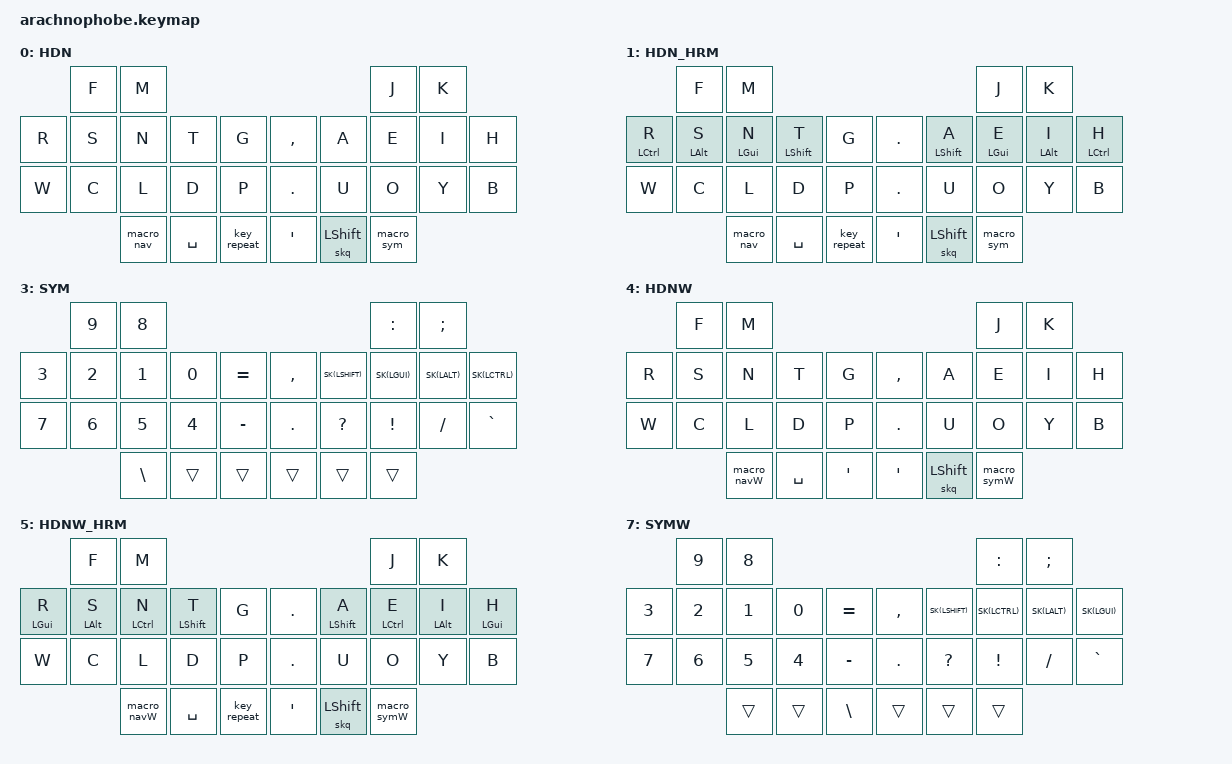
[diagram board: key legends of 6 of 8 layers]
/*
 * Copyright (c) 2020 The ZMK Contributors
 *
 * SPDX-License-Identifier: MIT
 */

#include <behaviors.dtsi>
#include <dt-bindings/zmk/keys.h>
#include <dt-bindings/zmk/rgb.h>
#include <dt-bindings/zmk/bt.h>
#include <dt-bindings/zmk/ext_power.h>
#include <dt-bindings/zmk/outputs.h>

#define HDN      0
#define HDN_HRM  1
#define NAV      2
#define SYM      3
#define HDNW     4
#define HDNW_HRM 5
#define NAVW     6
#define SYMW     7

#define SK(KEY) &nk KEY KEY

#define KEYS_L 0 1 4 5 6 7 8 14 14 15 16 17 18   // left-hand keys
#define KEYS_R 2 3 9 10 11 12 13 19 20 21 22 23  // right-hand keys
#define THUMBS 24 25 26 27 28 29                 // thumb keys

&sk {
  release-after-ms = <60000>;
  quick-release;
};

&caps_word {
  continue-list = <UNDERSCORE MINUS BACKSPACE K_CANCEL>;
};

&leader {
  timeout-ms = <500>;
};
/*                KEY POSITIONS

  ╭────────────────────────╮ ╭─────────────────────────╮
  │     0   1              │ │              2   3      │
  │ 4   5   6   7   8      │ │      9   10  11  12  13 │
  │ 14  15  16  17  18     │ │     19  20  21  22  23  │
  ╰───────╮     24  25  26 │ │ 27  28  29     ╭────────╯
          ╰────────────────╯ ╰────────────────╯            */


/ {
    behaviors {
    
        combos {
            #include "combos.dtsi"
        };

        macros {
          #include "macros.dtsi"
        };

        nk: not_so_sticky_key {
            compatible = "zmk,behavior-hold-tap";
            label = "NOT_SO_STICKY_KEY";
            #binding-cells = <2>;
            tapping_term_ms = <250>;
            flavor = "tap-preferred";
            bindings = <&kp>, <&sk>;
        };

        skq: sticky_key_quick_release {
            compatible = "zmk,behavior-sticky-key";
            label = "STICKY_KEY_QUICK_RELEASE";
            #binding-cells = <1>;
            bindings = <&kp>;
            quick-release;
            release-after-ms = <750>;
        };

    lal: layer-alpha {
        compatible = "zmk,behavior-hold-tap";
        label = "LAYER_ALPHA";
        #binding-cells = <2>;
        flavor = "balanced";
        tapping-term-ms = <170>;
        quick-tap-ms = <100>;
        global-quick-tap;
        bindings = <&mo>, <&kp>;
    };

        // Swapper for smart alt+tab depends on experimental branch: check west.yml
        swapper: swapper {
            compatible = "zmk,behavior-smart-interrupt";
            label = "SWAPPER";
            #binding-cells = <0>;
            bindings = <&kt LGUI>, <&kp TAB>, <&kt LGUI>;
            shared-key-positions = <16 18 28>;
            timeout-ms = <1000>;
        };

        // Swapper for smart alt+tab depends on experimental branch: check west.yml
        swapperw: swapperw {
            compatible = "zmk,behavior-smart-interrupt";
            label = "SWAPPERW";
            #binding-cells = <0>;
            bindings = <&kt LALT>, <&kp TAB>, <&kt LALT>;
            shared-key-positions = <16 18 28>;
            timeout-ms = <1000>;
        };

        gresc: grave_escape {
            compatible = "zmk,behavior-mod-morph";
            label = "GRAVE_ESCAPE";
            #binding-cells = <0>;
            bindings = <&kp N0>, <&kp DOT>;
            mods = <(MOD_LSFT|MOD_RSFT)>;
            masked_mods = <(MOD_LSFT|MOD_RSFT)>;
        };

        /* left-hand HRMs */
        hrml: hrml {
            compatible = "zmk,behavior-hold-tap";
            label = "hrml";
            #binding-cells = <2>;
            flavor = "balanced";
            tapping-term-ms = <280>;
            quick-tap-ms = <175>;                // double tapping same key allows for repeating
            global-quick-tap-ms = <150>;         // without PR #1387 use global-quick-tap instead
            bindings = <&kp>, <&kp>;
            hold-trigger-key-positions = <KEYS_R THUMBS>;
            hold-trigger-on-release;             // requires PR #1423
        };

        /* right-hand HRMs */
        hrmr: hrmr {
            compatible = "zmk,behavior-hold-tap";
            label = "hrmr";
            #binding-cells = <2>;
            flavor = "balanced";
            tapping-term-ms = <280>;
            quick-tap-ms = <175>;                // double tapping same key allows for repeating
            global-quick-tap-ms = <150>;         // without PR #1387 use global-quick-tap instead
            bindings = <&kp>, <&kp>;
            hold-trigger-key-positions = <KEYS_L THUMBS>;
            hold-trigger-on-release;             // requires PR #1423
        };

    };

    keymap {
        compatible = "zmk,keymap";

        hdn {
            label = "HDN";
            bindings = <
                   &kp F         &kp M                                                                     &kp J         &kp K         
     &kp R         &kp S         &kp N          &kp T          &kp G             &kp COMMA    &kp A        &kp E         &kp I         &kp H
     &kp W         &kp C         &kp L          &kp D          &kp P             &kp DOT      &kp U        &kp O         &kp Y         &kp B
//               ╰─────────────┴─────────────┼─────────────┤                               ├─────────────┼─────────────┴─────────────╯
                                 &macro_nav     &kp SPACE      &key_repeat       &kp SQT        &skq LSHFT   &macro_sym
            >;
        };

        hdn_hrm {
            label = "HDN_HRM";
            bindings = <
                   &kp F         &kp M                                                                     &kp J         &kp K         
     &hrml LCTRL R &hrml LALT S  &hrml LGUI N   &hrml LSHIFT T &kp G             &kp DOT      &hrmr LSHIFT A &hrmr LGUI E  &hrmr LALT I  &hrmr LCTRL H
     &kp W         &kp C         &kp L          &kp D          &kp P             &kp DOT      &kp U        &kp O         &kp Y         &kp B
//               ╰─────────────┴─────────────┼─────────────┤                               ├─────────────┼─────────────┴─────────────╯
                                 &macro_nav     &kp SPACE      &key_repeat       &kp SQT        &skq LSHFT   &macro_sym
            >;
        };

        navitation {
            label = "NAV";
            bindings = <
                       &kp ENTER     &kp BACKSPACE                                                 &kp UP        &kp LG(Q)  
     SK(LCTRL)         SK(LALT)      SK(LGUI)       SK(LSHIFT)   &kp DELETE      &kp LA(BACKSPACE) &kp LEFT      &kp DOWN      &kp RIGHT  &none
&kp LC(LA(LS(P)))      &kp LG(X)     &kp LG(C)      &kp LG(V)    &kp TAB         &kp LG(A)         &kp ENTER     &kp BACKSPACE &kp TAB    &kp LA(LC(LS(LG(K))))
//               ╰─────────────┴─────────────┼─────────────┤                               ├─────────────┼─────────────┴─────────────╯
                                                &trans   &trans   &trans       &trans   &trans   &trans
            >;
        };

        symbols {
            label = "SYM";
            bindings = <
                   &kp N9       &kp N8                                                                     &kp COLON    &kp SEMI      
     &kp N3        &kp N2       &kp N1         &kp N0          &kp EQUAL         &kp COMMA   SK(LSHIFT)    SK(LGUI)     SK(LALT)      SK(LCTRL)
     &kp N7        &kp N6       &kp N5         &kp N4          &kp MINUS         &kp DOT     &kp QMARK     &kp EXCL     &kp SLASH     &kp GRAVE
//               ╰─────────────┴─────────────┼─────────────┤                               ├─────────────┼─────────────┴─────────────╯
                                   &kp BACKSLASH    &trans     &trans            &trans        &trans        &trans
            >;
        };

        hdnw {
            label = "HDNW";
            bindings = <
                   &kp F         &kp M                                                                     &kp J         &kp K         
     &kp R         &kp S         &kp N          &kp T          &kp G             &kp COMMA    &kp A        &kp E         &kp I         &kp H
     &kp W         &kp C         &kp L          &kp D          &kp P             &kp DOT      &kp U        &kp O         &kp Y         &kp B
//               ╰─────────────┴─────────────┼─────────────┤                               ├─────────────┼─────────────┴─────────────╯
                                 &macro_navW     &kp SPACE      &kp SQT          &kp SQT        &skq LSHFT   &macro_symW
            >;
        };

        hdnw_hrm {
            label = "HDNW_HRM";
            bindings = <
                   &kp F         &kp M                                                                     &kp J         &kp K         
     &hrml LGUI R &hrml LALT S  &hrml LCTRL N   &hrml LSHIFT T &kp G             &kp DOT      &hrmr LSHIFT A &hrmr LCTRL E  &hrmr LALT I  &hrmr LGUI H
     &kp W         &kp C         &kp L          &kp D          &kp P             &kp DOT      &kp U        &kp O         &kp Y         &kp B
//               ╰─────────────┴─────────────┼─────────────┤                               ├─────────────┼─────────────┴─────────────╯
                                 &macro_navW     &kp SPACE      &key_repeat       &kp SQT        &skq LSHFT   &macro_symW
            >;
        };

        navitation_windows {
            label = "NAVW";
            bindings = <
                       &kp ENTER     &kp BACKSPACE                                                 &kp UP        &kp LA(F4)  
     SK(LGUI)          SK(LALT)      SK(LCTRL)      SK(LSHIFT)   &kp DELETE      &kp LC(BACKSPACE) &kp LEFT      &kp DOWN      &kp RIGHT  &kp F2
&kp LC(LA(LS(P)))      &kp LC(X)     &kp LC(C)      &kp LC(V)    &kp TAB         &kp LC(A)         &kp ENTER     &kp BACKSPACE &kp TAB    &none
//               ╰─────────────┴─────────────┼─────────────┤                               ├─────────────┼─────────────┴─────────────╯
                                                &trans   &trans   &trans       &trans   &trans   &trans
            >;
        };

        symbols_windows {
            label = "SYMW";
            bindings = <
                   &kp N9       &kp N8                                                                     &kp COLON    &kp SEMI      
     &kp N3        &kp N2       &kp N1         &kp N0          &kp EQUAL         &kp COMMA   SK(LSHIFT)    SK(LCTRL)     SK(LALT)      SK(LGUI)
     &kp N7        &kp N6       &kp N5         &kp N4          &kp MINUS         &kp DOT     &kp QMARK     &kp EXCL     &kp SLASH     &kp GRAVE
//               ╰─────────────┴─────────────┼─────────────┤                               ├─────────────┼─────────────┴─────────────╯
                                   &trans    &trans     &kp BACKSLASH            &trans        &trans        &trans
            >;
        };

    };
};
